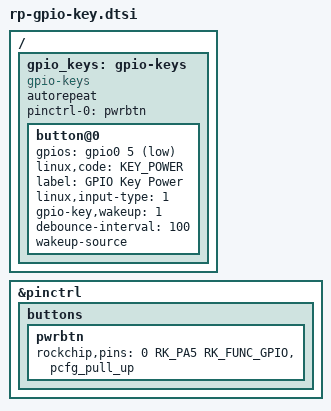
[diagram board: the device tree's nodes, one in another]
/ {

    gpio_keys:gpio-keys {
        status = "okay";
        compatible = "gpio-keys";
        #address-cells = <1>;
        #size-cells = <0>;
        autorepeat;

        pinctrl-names = "default";
        pinctrl-0 = <&pwrbtn>;

        button@0 {
            gpios = <&gpio0 5 GPIO_ACTIVE_LOW>;
            linux,code = <KEY_POWER>;
            label = "GPIO Key Power";
            linux,input-type = <1>;
            gpio-key,wakeup = <1>;
            debounce-interval = <100>;
            wakeup-source;
        };
    };
    
    
};


&pinctrl {
    buttons {
        pwrbtn: pwrbtn {
            rockchip,pins = <0 RK_PA5 RK_FUNC_GPIO &pcfg_pull_up>;
        };
    };
};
